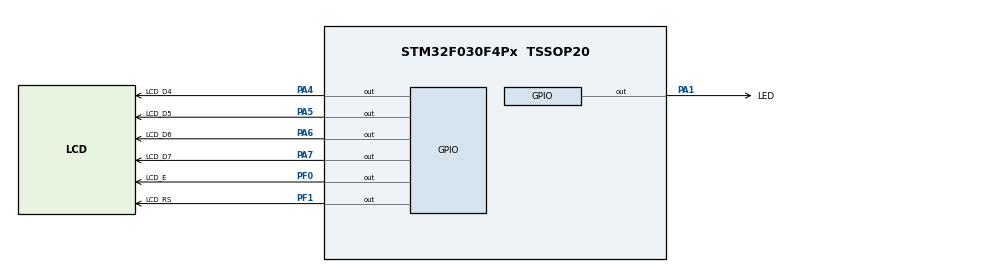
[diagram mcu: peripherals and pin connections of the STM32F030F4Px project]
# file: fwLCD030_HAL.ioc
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Mcu.Family=STM32F0
Mcu.Name=STM32F030F4Px
Mcu.Package=TSSOP20
PA1.GPIO_Label=LED
PA1.GPIO_Speed=GPIO_SPEED_FREQ_HIGH
PA1.PinState=GPIO_PIN_RESET
PA1.Signal=GPIO_Output
PA13.Mode=Serial_Wire
PA13.Signal=SYS_SWDIO
PA14.Mode=Serial_Wire
PA14.Signal=SYS_SWCLK
PA4.GPIO_Label=LCD_D4
PA4.GPIO_Speed=GPIO_SPEED_FREQ_HIGH
PA4.Signal=GPIO_Output
PA5.GPIO_Label=LCD_D5
PA5.GPIO_Speed=GPIO_SPEED_FREQ_HIGH
PA5.Signal=GPIO_Output
PA6.GPIO_Label=LCD_D6
PA6.GPIO_Speed=GPIO_SPEED_FREQ_HIGH
PA6.Signal=GPIO_Output
PA7.GPIO_Label=LCD_D7
PA7.GPIO_Speed=GPIO_SPEED_FREQ_HIGH
PA7.Signal=GPIO_Output
PF0-OSC_IN.GPIO_Label=LCD_E
PF0-OSC_IN.GPIO_Speed=GPIO_SPEED_FREQ_HIGH
PF0-OSC_IN.Signal=GPIO_Output
PF1-OSC_OUT.GPIO_Label=LCD_RS
PF1-OSC_OUT.GPIO_Speed=GPIO_SPEED_FREQ_HIGH
PF1-OSC_OUT.Signal=GPIO_Output
ProjectManager.HeapSize=0x200
ProjectManager.StackSize=0x400
ProjectManager.TargetToolchain=SW4STM32
board=fwLCD030_HAL

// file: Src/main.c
/**
  ******************************************************************************
  * File Name          : main.c
  * Description        : Main program body
  ******************************************************************************
  ** This notice applies to any and all portions of this file
  * that are not between comment pairs USER CODE BEGIN and
  * USER CODE END. Other portions of this file, whether
  * inserted by the user or by software development tools
  * are owned by their respective copyright owners.
  *
  * COPYRIGHT(c) 2017 STMicroelectronics
  *
  * Redistribution and use in source and binary forms, with or without modification,
  * are permitted provided that the following conditions are met:
  *   1. Redistributions of source code must retain the above copyright notice,
  *      this list of conditions and the following disclaimer.
  *   2. Redistributions in binary form must reproduce the above copyright notice,
  *      this list of conditions and the following disclaimer in the documentation
  *      and/or other materials provided with the distribution.
  *   3. Neither the name of STMicroelectronics nor the names of its contributors
  *      may be used to endorse or promote products derived from this software
  *      without specific prior written permission.
  *
  * THIS SOFTWARE IS PROVIDED BY THE COPYRIGHT HOLDERS AND CONTRIBUTORS "AS IS"
  * AND ANY EXPRESS OR IMPLIED WARRANTIES, INCLUDING, BUT NOT LIMITED TO, THE
  * IMPLIED WARRANTIES OF MERCHANTABILITY AND FITNESS FOR A PARTICULAR PURPOSE ARE
  * DISCLAIMED. IN NO EVENT SHALL THE COPYRIGHT HOLDER OR CONTRIBUTORS BE LIABLE
  * FOR ANY DIRECT, INDIRECT, INCIDENTAL, SPECIAL, EXEMPLARY, OR CONSEQUENTIAL
  * DAMAGES (INCLUDING, BUT NOT LIMITED TO, PROCUREMENT OF SUBSTITUTE GOODS OR
  * SERVICES; LOSS OF USE, DATA, OR PROFITS; OR BUSINESS INTERRUPTION) HOWEVER
  * CAUSED AND ON ANY THEORY OF LIABILITY, WHETHER IN CONTRACT, STRICT LIABILITY,
  * OR TORT (INCLUDING NEGLIGENCE OR OTHERWISE) ARISING IN ANY WAY OUT OF THE USE
  * OF THIS SOFTWARE, EVEN IF ADVISED OF THE POSSIBILITY OF SUCH DAMAGE.
  *
  ******************************************************************************
  */
#include "main.h"
#include "stm32f0xx_hal.h"
#include "gpio.h"

/* USER CODE BEGIN PV */
/* Private variables ---------------------------------------------------------*/

/* USER CODE END PV */

void SystemClock_Config(void);

/* USER CODE BEGIN PFP */
/* Private function prototypes -----------------------------------------------*/

/* USER CODE END PFP */

int main(void)
{

  /* MCU Configuration----------------------------------------------------------*/

  /* Reset of all peripherals, Initializes the Flash interface and the Systick. */
  HAL_Init();

  /* Configure the system clock */
  SystemClock_Config();

  /* Initialize all configured peripherals */
  MX_GPIO_Init();

  /* USER CODE BEGIN 2 */
  InitializeLCD(); //Инициализация дисплея
  ClearLCDScreen(); //Очистка дисплея от мусора
  Cursor(0,2); //Установка курсора
  PrintStr("Orange PI PC"); //Написание текста
  Cursor(1,0);
  PrintStr("T1 = 71 T2 = 71");
  /* USER CODE END 2 */

  /* Infinite loop */
  while (1)
  {

  /* USER CODE BEGIN 3 */
	  HAL_GPIO_TogglePin(LED_GPIO_Port, LED_Pin);
	  HAL_Delay(200);
  }
  /* USER CODE END 3 */

}

/** System Clock Configuration
*/
void SystemClock_Config(void)
{

  RCC_OscInitTypeDef RCC_OscInitStruct;
  RCC_ClkInitTypeDef RCC_ClkInitStruct;

    /**Initializes the CPU, AHB and APB busses clocks
    */
  RCC_OscInitStruct.OscillatorType = RCC_OSCILLATORTYPE_HSI;
  RCC_OscInitStruct.HSIState = RCC_HSI_ON;
  RCC_OscInitStruct.HSICalibrationValue = 16;
  RCC_OscInitStruct.PLL.PLLState = RCC_PLL_NONE;
  if (HAL_RCC_OscConfig(&RCC_OscInitStruct) != HAL_OK)
  {
    _Error_Handler(__FILE__, __LINE__);
  }

    /**Initializes the CPU, AHB and APB busses clocks
    */
  RCC_ClkInitStruct.ClockType = RCC_CLOCKTYPE_HCLK|RCC_CLOCKTYPE_SYSCLK
                              |RCC_CLOCKTYPE_PCLK1;
  RCC_ClkInitStruct.SYSCLKSource = RCC_SYSCLKSOURCE_HSI;
  RCC_ClkInitStruct.AHBCLKDivider = RCC_SYSCLK_DIV1;
  RCC_ClkInitStruct.APB1CLKDivider = RCC_HCLK_DIV1;

  if (HAL_RCC_ClockConfig(&RCC_ClkInitStruct, FLASH_LATENCY_0) != HAL_OK)
  {
    _Error_Handler(__FILE__, __LINE__);
  }

    /**Configure the Systick interrupt time
    */
  HAL_SYSTICK_Config(HAL_RCC_GetHCLKFreq()/1000);

    /**Configure the Systick
    */
  HAL_SYSTICK_CLKSourceConfig(SYSTICK_CLKSOURCE_HCLK);

  /* SysTick_IRQn interrupt configuration */
  HAL_NVIC_SetPriority(SysTick_IRQn, 0, 0);
}

void _Error_Handler(char * file, int line)
{
  while(1)
  {
  }
}

/************************ (C) COPYRIGHT STMicroelectronics *****END OF FILE****/
